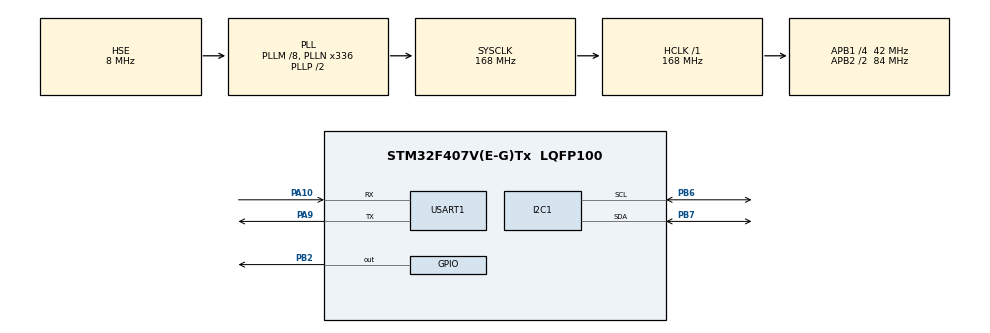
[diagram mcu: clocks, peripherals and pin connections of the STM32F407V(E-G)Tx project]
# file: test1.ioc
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Mcu.Family=STM32F4
Mcu.Name=STM32F407V(E-G)Tx
Mcu.Package=LQFP100
NVIC.I2C1_ER_IRQn=true\:0\:0\:false\:false\:true\:true\:true\:true
NVIC.I2C1_EV_IRQn=true\:0\:0\:false\:false\:true\:true\:true\:true
NVIC.PriorityGroup=NVIC_PRIORITYGROUP_4
NVIC.USART1_IRQn=true\:0\:0\:false\:false\:true\:true\:true\:true
PA10.Mode=Asynchronous
PA10.Signal=USART1_RX
PA13.Mode=Serial_Wire
PA13.Signal=SYS_JTMS-SWDIO
PA14.Mode=Serial_Wire
PA14.Signal=SYS_JTCK-SWCLK
PA9.Mode=Asynchronous
PA9.Signal=USART1_TX
PB2.GPIO_PuPd=GPIO_PULLUP
PB2.GPIO_Speed=GPIO_SPEED_FREQ_MEDIUM
PB2.PinState=GPIO_PIN_SET
PB2.Signal=GPIO_Output
PB6.Mode=I2C
PB6.Signal=I2C1_SCL
PB7.Mode=I2C
PB7.Signal=I2C1_SDA
PH0-OSC_IN.Mode=HSE-External-Oscillator
PH0-OSC_IN.Signal=RCC_OSC_IN
PH1-OSC_OUT.Mode=HSE-External-Oscillator
PH1-OSC_OUT.Signal=RCC_OSC_OUT
ProjectManager.HeapSize=0x200
ProjectManager.StackSize=0x400
ProjectManager.TargetToolchain=MDK-ARM V5.32
RCC.48MHZClocksFreq_Value=84000000
RCC.AHBFreq_Value=168000000
RCC.APB1CLKDivider=RCC_HCLK_DIV4
RCC.APB1Freq_Value=42000000
RCC.APB1TimFreq_Value=84000000
RCC.APB2CLKDivider=RCC_HCLK_DIV2
RCC.APB2Freq_Value=84000000
RCC.APB2TimFreq_Value=168000000
RCC.CortexFreq_Value=168000000
RCC.HCLKFreq_Value=168000000
RCC.HSE_VALUE=8000000
RCC.HSI_VALUE=16000000
RCC.LSE_VALUE=32768
RCC.PLLM=8
RCC.PLLN=336
RCC.PLLSourceVirtual=RCC_PLLSOURCE_HSE
RCC.SYSCLKFreq_VALUE=168000000
RCC.SYSCLKSource=RCC_SYSCLKSOURCE_PLLCLK
RCC.VCOOutputFreq_Value=336000000
USART1.VirtualMode=VM_ASYNC
board=custom

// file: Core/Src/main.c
/* USER CODE BEGIN Header */
/**
  ******************************************************************************
  * @file           : main.c
  * @brief          : Main program body
  ******************************************************************************
  * @attention
  *
  * Copyright (c) 2026 STMicroelectronics.
  * All rights reserved.
  *
  * This software is licensed under terms that can be found in the LICENSE file
  * in the root directory of this software component.
  * If no LICENSE file comes with this software, it is provided AS-IS.
  *
  ******************************************************************************
  */
/* USER CODE END Header */
#include "main.h"

/* USER CODE BEGIN Includes */
#include "bootloader.h"
#include "display_ota.h"
#include "oled.h"
#include "test_bootloader_mcu.h"
/* USER CODE END Includes */

/* USER CODE END Includes */

I2C_HandleTypeDef hi2c1;

UART_HandleTypeDef huart1;

void SystemClock_Config(void);
static void MX_GPIO_Init(void);
static void MX_USART1_UART_Init(void);
static void MX_I2C1_Init(void);

int main(void)
{

  /* MCU Configuration--------------------------------------------------------*/

  /* Reset of all peripherals, Initializes the Flash interface and the Systick. */
  HAL_Init();

  /* Configure the system clock */
  SystemClock_Config();

  /* Initialize all configured peripherals */
  MX_GPIO_Init();
  MX_USART1_UART_Init();
  MX_I2C1_Init();
  /* USER CODE BEGIN 2 */

  /**
   * 配置 PA0 为输入（Boot 按键）
   * 电路：按下接 VCC (3.3V)，松开接地
   * 配置：下拉输入，按下为高电平
   */
  GPIO_InitTypeDef GPIO_InitStruct = {0};
  GPIO_InitStruct.Pin = GPIO_PIN_0;
  GPIO_InitStruct.Mode = GPIO_MODE_INPUT;
  GPIO_InitStruct.Pull = GPIO_PULLDOWN;  /* 下拉，按下为高电平 */
  HAL_GPIO_Init(GPIOA, &GPIO_InitStruct);

  /* 初始化 OLED - 启动时立即显示启动画面 */
  OLED_Init();
  OLED_Clear();
  OLED_Refresh();

  /* 显示启动画面 - 用户可以看到 Bootloader 正在启动 */
  OLED_ShowString(20, 0, (uint8_t *)"=== Bootloader ===", 8, 1);
  OLED_ShowString(10, 2, (uint8_t *)"Checking firmware...", 8, 1);
  OLED_Refresh();
  HAL_Delay(500);

  /* 初始化 Bootloader - 设置状态、缓冲区、启动 UART 接收 */
  Bootloader_Init();

  /**
   * 检查 PA0 按键 - 按下（高电平）进入 Boot 模式
   * 流程：
   * 1. 检测 PA0 是否为高电平
   * 2. 等待按键释放
   * 3. 初始化 OTA 显示
   * 4. 进入 Bootloader 主循环
   */
  if (HAL_GPIO_ReadPin(GPIOA, GPIO_PIN_0) == GPIO_PIN_SET) {
      /* 按键按下，等待释放 */
      OLED_ShowString(0, 4, (uint8_t *)"Button pressed!", 8, 1);
      OLED_Refresh();
      Bootloader_SendResponse("Button pressed, enter boot mode");

      while (HAL_GPIO_ReadPin(GPIOA, GPIO_PIN_0) == GPIO_PIN_SET) {
          HAL_Delay(10);
      }

      /* 直接进入 Bootloader 模式 */
      Display_OTA_Init();
      Display_OTA_ShowMain();
      Display_OTA_SetState(OTA_DISP_RECEIVING);

      Bootloader_SendResponse("Entering bootloader mode (button)...");
      Bootloader_Run();  /* 进入主循环，永不返回 */
  }

  /**
   * 检查是否应该进入 Bootloader
   * 条件：
   * 1. Boot 魔数已设置（APP 发送 ota_enter 命令）
   * 2. 回滚标志已设置（OTA 失败需要恢复）
   * 3. APP 无效（向量表错误、CRC 不匹配）
   */
  if (Bootloader_ShouldEnter()) {
      /* 检查回滚标志 */
      if (Bootloader_ShouldRollback()) {
          /* A/B 分区回滚：切换回旧分区 */
          OLED_ShowString(0, 4, (uint8_t *)"Rollback partition...", 8, 1);
          OLED_Refresh();

          Bootloader_SendResponse("Rollback: switching partition...");
          Bootloader_SwitchPartition();
          Bootloader_ClearRollbackFlag();
          Bootloader_SendResponse("Rollback done, resetting...");
          HAL_Delay(100);
          NVIC_SystemReset();  /* 复位后会重新运行 Bootloader */
      }

      /* 进入 Bootloader 模式 - 显示 OTA 界面 */
      Display_OTA_Init();
      Display_OTA_ShowMain();
      Display_OTA_SetState(OTA_DISP_RECEIVING);

      Bootloader_SendResponse("Entering bootloader mode...");
      Bootloader_Run();  /* 进入主循环，等待 OTA 命令 */
  } else {
      /**
       * 跳转到 Application
       * 条件：没有 Boot 魔数，没有回滚标志，APP 有效
       */
      OLED_ShowString(0, 4, (uint8_t *)"Jumping to app...", 8, 1);
      OLED_Refresh();
      HAL_Delay(200);

      Bootloader_SendResponse("No boot flag, jumping to app...");
      Bootloader_JumpToApp();  /* 跳转到 APP，永不返回 */

      /* 如果跳转失败（APP 无效），进入错误状态 */
      OLED_Clear();
      OLED_ShowString(20, 0, (uint8_t *)"=== ERROR ===", 8, 1);
      OLED_ShowString(0, 3, (uint8_t *)"Jump failed!", 8, 1);
      OLED_ShowString(0, 5, (uint8_t *)"Stay in bootloader", 8, 1);
      OLED_Refresh();

      Bootloader_SendResponse("ERROR:Jump failed, staying in bootloader");
      while (1) {
          HAL_GPIO_TogglePin(LED_STATUS_GPIO_Port, LED_STATUS_Pin);  /* 快速闪烁 */
          IWDG->KR = 0xAAAA;
          HAL_Delay(100);
      }
  }

  /* Infinite loop */
  while (1)
  {

  }
}

void SystemClock_Config(void)
{
  RCC_OscInitTypeDef RCC_OscInitStruct = {0};
  RCC_ClkInitTypeDef RCC_ClkInitStruct = {0};

  /** Configure the main internal regulator output voltage
  */
  __HAL_RCC_PWR_CLK_ENABLE();
  __HAL_PWR_VOLTAGESCALING_CONFIG(PWR_REGULATOR_VOLTAGE_SCALE1);

  /** Initializes the RCC Oscillators according to the specified parameters
  * in the RCC_OscInitTypeDef structure.
  */
  RCC_OscInitStruct.OscillatorType = RCC_OSCILLATORTYPE_HSE;
  RCC_OscInitStruct.HSEState = RCC_HSE_ON;
  RCC_OscInitStruct.PLL.PLLState = RCC_PLL_ON;
  RCC_OscInitStruct.PLL.PLLSource = RCC_PLLSOURCE_HSE;
  RCC_OscInitStruct.PLL.PLLM = 8;
  RCC_OscInitStruct.PLL.PLLN = 336;
  RCC_OscInitStruct.PLL.PLLP = RCC_PLLP_DIV2;
  RCC_OscInitStruct.PLL.PLLQ = 4;
  if (HAL_RCC_OscConfig(&RCC_OscInitStruct) != HAL_OK)
  {
    Error_Handler();
  }

  /** Initializes the CPU, AHB and APB buses clocks
  */
  RCC_ClkInitStruct.ClockType = RCC_CLOCKTYPE_HCLK|RCC_CLOCKTYPE_SYSCLK
                              |RCC_CLOCKTYPE_PCLK1|RCC_CLOCKTYPE_PCLK2;
  RCC_ClkInitStruct.SYSCLKSource = RCC_SYSCLKSOURCE_PLLCLK;
  RCC_ClkInitStruct.AHBCLKDivider = RCC_SYSCLK_DIV1;
  RCC_ClkInitStruct.APB1CLKDivider = RCC_HCLK_DIV4;
  RCC_ClkInitStruct.APB2CLKDivider = RCC_HCLK_DIV2;

  if (HAL_RCC_ClockConfig(&RCC_ClkInitStruct, FLASH_LATENCY_5) != HAL_OK)
  {
    Error_Handler();
  }
}

static void MX_I2C1_Init(void)
{

  hi2c1.Instance = I2C1;
  hi2c1.Init.ClockSpeed = 100000;
  hi2c1.Init.DutyCycle = I2C_DUTYCYCLE_2;
  hi2c1.Init.OwnAddress1 = 0;
  hi2c1.Init.AddressingMode = I2C_ADDRESSINGMODE_7BIT;
  hi2c1.Init.DualAddressMode = I2C_DUALADDRESS_DISABLE;
  hi2c1.Init.OwnAddress2 = 0;
  hi2c1.Init.GeneralCallMode = I2C_GENERALCALL_DISABLE;
  hi2c1.Init.NoStretchMode = I2C_NOSTRETCH_DISABLE;
  if (HAL_I2C_Init(&hi2c1) != HAL_OK)
  {
    Error_Handler();
  }

}

static void MX_USART1_UART_Init(void)
{

  huart1.Instance = USART1;
  huart1.Init.BaudRate = 115200;
  huart1.Init.WordLength = UART_WORDLENGTH_8B;
  huart1.Init.StopBits = UART_STOPBITS_1;
  huart1.Init.Parity = UART_PARITY_NONE;
  huart1.Init.Mode = UART_MODE_TX_RX;
  huart1.Init.HwFlowCtl = UART_HWCONTROL_NONE;
  huart1.Init.OverSampling = UART_OVERSAMPLING_16;
  if (HAL_UART_Init(&huart1) != HAL_OK)
  {
    Error_Handler();
  }

}

static void MX_GPIO_Init(void)
{
  GPIO_InitTypeDef GPIO_InitStruct = {0};

  /* GPIO Ports Clock Enable */
  __HAL_RCC_GPIOH_CLK_ENABLE();
  __HAL_RCC_GPIOB_CLK_ENABLE();
  __HAL_RCC_GPIOA_CLK_ENABLE();

  /*Configure GPIO pin Output Level */
  HAL_GPIO_WritePin(GPIOB, GPIO_PIN_2, GPIO_PIN_SET);

  /*Configure GPIO pin : PB2 */
  GPIO_InitStruct.Pin = GPIO_PIN_2;
  GPIO_InitStruct.Mode = GPIO_MODE_OUTPUT_PP;
  GPIO_InitStruct.Pull = GPIO_PULLUP;
  GPIO_InitStruct.Speed = GPIO_SPEED_FREQ_MEDIUM;
  HAL_GPIO_Init(GPIOB, &GPIO_InitStruct);

}

void Error_Handler(void)
{
  __disable_irq();
  while (1)
  {
  }
}
